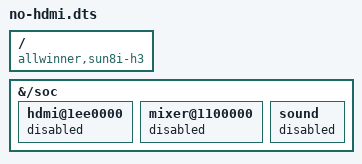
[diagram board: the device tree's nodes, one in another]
/dts-v1/;

/ {
    compatible = "allwinner,sun8i-h3","allwinner,sun50i-h5","friendlyarm,nanopi-neo2";

    fragment@0 {        
        target-path = "/soc";
        __overlay__ {
            hdmi@1ee0000 {
                        status = "disabled";
            };
            mixer@1100000 {
                         status = "disabled";
            };
            sound {
                         status = "disabled";
            };
        };
    };

    fragment@1 {
        target-path = [2f 00];
        __overlay__ {
              sound {
                         status = "disabled";
              };
        };
    };
};

// vim: et ts=4 sw=4 foldmethod=indent
